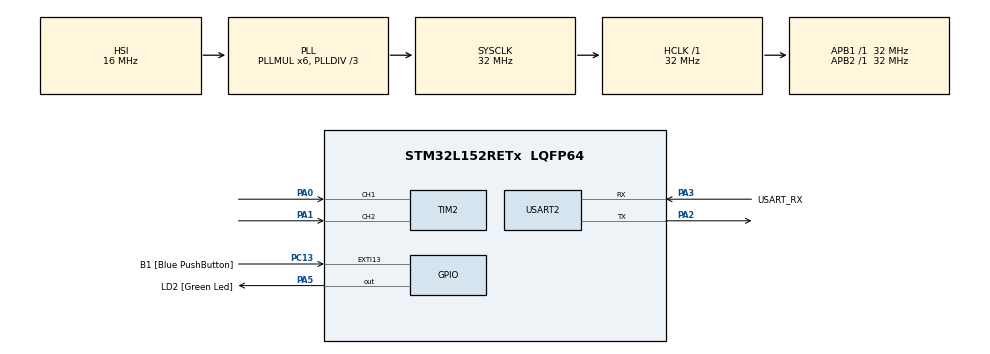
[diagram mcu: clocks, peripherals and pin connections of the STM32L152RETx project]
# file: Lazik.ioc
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Mcu.Family=STM32L1
Mcu.Name=STM32L152RETx
Mcu.Package=LQFP64
NVIC.PriorityGroup=NVIC_PRIORITYGROUP_0
NVIC.TIM10_IRQn=true\:0\:0\:false\:false\:true\:true\:true\:true
NVIC.USART2_IRQn=true\:0\:0\:false\:false\:true\:true\:true\:true
PA0-WKUP1.GPIO_Speed=GPIO_SPEED_FREQ_VERY_HIGH
PA0-WKUP1.Signal=S_TIM2_CH1_ETR
PA1.GPIO_Speed=GPIO_SPEED_FREQ_VERY_HIGH
PA1.Signal=S_TIM2_CH2
PA13.GPIO_Label=TMS
PA13.Signal=SYS_JTMS-SWDIO
PA14.GPIO_Label=TCK
PA14.Signal=SYS_JTCK-SWCLK
PA2.Mode=Asynchronous
PA2.Signal=USART2_TX
PA3.GPIO_Label=USART_RX
PA3.Mode=Asynchronous
PA3.Signal=USART2_RX
PA5.GPIO_Label=LD2 [Green Led]
PA5.Signal=GPIO_Output
PB3.GPIO_Label=SWO
PB3.Signal=SYS_JTDO-TRACESWO
PC13-WKUP2.GPIO_Label=B1 [Blue PushButton]
PC13-WKUP2.Signal=GPXTI13
PC14-OSC32_IN.Signal=RCC_OSC32_IN
PC15-OSC32_OUT.Signal=RCC_OSC32_OUT
PH0-OSC_IN.Signal=RCC_OSC_IN
PH1-OSC_OUT.Signal=RCC_OSC_OUT
ProjectManager.HeapSize=0x200
ProjectManager.StackSize=0x400
ProjectManager.TargetToolchain=STM32CubeIDE
RCC.48MHZClocksFreq_Value=48000000
RCC.AHBFreq_Value=32000000
RCC.APB1Freq_Value=32000000
RCC.APB1TimFreq_Value=32000000
RCC.APB2Freq_Value=32000000
RCC.APB2TimFreq_Value=32000000
RCC.HCLKFreq_Value=32000000
RCC.HSE_VALUE=8000000
RCC.HSI_VALUE=16000000
RCC.LSE_VALUE=32768
RCC.MSI_VALUE=2097000
RCC.PLLDIV=RCC_PLL_DIV3
RCC.PLLMUL=RCC_PLL_MUL6
RCC.RTCClockSelectionVirtual=RCC_RTCCLKSOURCE_LSE
RCC.SYSCLKFreq_VALUE=32000000
RCC.SYSCLKSource=RCC_SYSCLKSOURCE_PLLCLK
RCC.USBOutput=48000000
RCC.VCOOutputFreq_Value=96000000
SH.S_TIM2_CH1_ETR.0=TIM2_CH1,Encoder_Interface
SH.S_TIM2_CH2.0=TIM2_CH2,Encoder_Interface
TIM10.Channel=TIM_CHANNEL_1
TIM10.Period=1000-1
TIM10.Prescaler=3200-1
TIM2.EncoderMode=TIM_ENCODERMODE_TI12
TIM2.IC1Filter=15
TIM2.IC2Filter=15
USART2.VirtualMode=VM_ASYNC
VP_TIM10_VS_ClockSourceINT.Mode=Internal
VP_TIM10_VS_no_output1.Mode=Output Compare1 No Output
board=NUCLEO-L152RE

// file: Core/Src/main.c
/* USER CODE BEGIN Header */
/**
  ******************************************************************************
  * @file           : main.c
  * @brief          : Main program body
  ******************************************************************************
  * @attention
  *
  * Copyright (c) 2024 STMicroelectronics.
  * All rights reserved.
  *
  * This software is licensed under terms that can be found in the LICENSE file
  * in the root directory of this software component.
  * If no LICENSE file comes with this software, it is provided AS-IS.
  *
  ******************************************************************************
  */
/* USER CODE END Header */
#include "main.h"
#include "tim.h"
#include "usart.h"
#include "gpio.h"

/* USER CODE BEGIN Includes */
#include "motor.h"
/* USER CODE END Includes */

void SystemClock_Config(void);

/* USER CODE BEGIN 0 */
motor_str motorA;
/* USER CODE END 0 */

int main(void)
{

  /* MCU Configuration--------------------------------------------------------*/

  /* Reset of all peripherals, Initializes the Flash interface and the Systick. */
  HAL_Init();

  /* Configure the system clock */
  SystemClock_Config();

  /* Initialize all configured peripherals */
  MX_GPIO_Init();
  MX_TIM2_Init();
  MX_USART2_UART_Init();
  MX_TIM10_Init();
  /* USER CODE BEGIN 2 */
  HAL_TIM_Encoder_Start(&htim2, TIM_CHANNEL_ALL);

  //drv8835_init();
  //HAL_TIM_PWM_Start(&htim3, TIM_CHANNEL_1);
  motor_str_init(&motorA, &htim2);
  HAL_TIM_Base_Start_IT(&htim10);

  //int pwm = 0, dir = CCW, inc_dec = 1;
  //uint32_t time_tick = HAL_GetTick();
  //uint32_t max_time = 20;

  //drv8835_set_motorA_direction(dir);
  //drv8835_set_motorA_speed(pwm);
  /* USER CODE END 2 */

  /* Infinite loop */
  /* USER CODE BEGIN WHILE */
  while (1)
  {
	 // htim2.Instance->CNT;

//	  __HAL_TIM_SET_COMPARE(&htim3, TIM_CHANNEL_1, 20);
//	  HAL_Delay(1000);
//	  __HAL_TIM_SET_COMPARE(&htim3, TIM_CHANNEL_1, 50);
//	  HAL_Delay(1000);
//	  __HAL_TIM_SET_COMPARE(&htim3, TIM_CHANNEL_1, 90);
//	  HAL_Delay(1000);
//	  __HAL_TIM_SET_COMPARE(&htim3, TIM_CHANNEL_1, 100);
//	  HAL_Delay(1000);
    /* USER CODE END WHILE */

  }
}

void SystemClock_Config(void)
{
  RCC_OscInitTypeDef RCC_OscInitStruct = {0};
  RCC_ClkInitTypeDef RCC_ClkInitStruct = {0};

  /** Configure the main internal regulator output voltage
  */
  __HAL_PWR_VOLTAGESCALING_CONFIG(PWR_REGULATOR_VOLTAGE_SCALE1);

  /** Initializes the RCC Oscillators according to the specified parameters
  * in the RCC_OscInitTypeDef structure.
  */
  RCC_OscInitStruct.OscillatorType = RCC_OSCILLATORTYPE_HSI;
  RCC_OscInitStruct.HSIState = RCC_HSI_ON;
  RCC_OscInitStruct.HSICalibrationValue = RCC_HSICALIBRATION_DEFAULT;
  RCC_OscInitStruct.PLL.PLLState = RCC_PLL_ON;
  RCC_OscInitStruct.PLL.PLLSource = RCC_PLLSOURCE_HSI;
  RCC_OscInitStruct.PLL.PLLMUL = RCC_PLL_MUL6;
  RCC_OscInitStruct.PLL.PLLDIV = RCC_PLL_DIV3;
  if (HAL_RCC_OscConfig(&RCC_OscInitStruct) != HAL_OK)
  {
    Error_Handler();
  }

  /** Initializes the CPU, AHB and APB buses clocks
  */
  RCC_ClkInitStruct.ClockType = RCC_CLOCKTYPE_HCLK|RCC_CLOCKTYPE_SYSCLK
                              |RCC_CLOCKTYPE_PCLK1|RCC_CLOCKTYPE_PCLK2;
  RCC_ClkInitStruct.SYSCLKSource = RCC_SYSCLKSOURCE_PLLCLK;
  RCC_ClkInitStruct.AHBCLKDivider = RCC_SYSCLK_DIV1;
  RCC_ClkInitStruct.APB1CLKDivider = RCC_HCLK_DIV1;
  RCC_ClkInitStruct.APB2CLKDivider = RCC_HCLK_DIV1;

  if (HAL_RCC_ClockConfig(&RCC_ClkInitStruct, FLASH_LATENCY_1) != HAL_OK)
  {
    Error_Handler();
  }
}

/* USER CODE BEGIN 4 */
void HAL_TIM_PeriodElapsedCallback(TIM_HandleTypeDef *htim)
{
	if(htim->Instance == TIM10)
	{
		motor_calculate_speed(&motorA);
	}
}
/* USER CODE END 4 */

void Error_Handler(void)
{
  __disable_irq();
  while (1)
  {
  }
}
